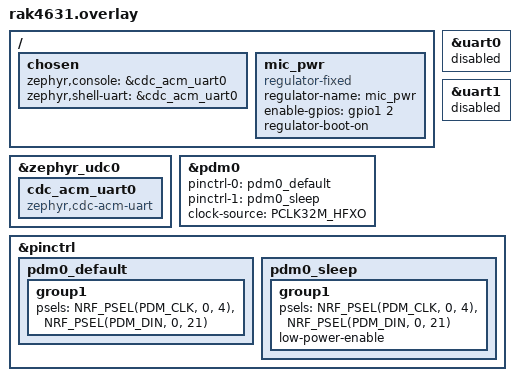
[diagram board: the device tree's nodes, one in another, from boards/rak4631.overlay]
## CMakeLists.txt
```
# SPDX-License-Identifier: Apache-2.0

cmake_minimum_required(VERSION 3.20.0)

find_package(Zephyr REQUIRED HINTS $ENV{ZEPHYR_BASE})
project(rak18030)

target_sources(app PRIVATE src/main.c)
```

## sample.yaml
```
sample:
  name: RAK18030
tests:
  sample.sensor.rak18030:
    platform_allow:
      - rak4631
    tags: rak
    build_only: true
  sample.sensor.rak18030.sleep:
    platform_allow:
      - rak4631
    extra_args: EXTRA_CONF_FILE=overlay_sleep_rak4631.conf
    tags: rak
    build_only: true
```

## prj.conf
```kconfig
CONFIG_GPIO=y
CONFIG_SPI=y
CONFIG_LORA=y
CONFIG_REGULATOR=y

CONFIG_AUDIO=y
CONFIG_AUDIO_DMIC=y

CONFIG_MAIN_STACK_SIZE=4096

CONFIG_PRINTK=y
CONFIG_BOOT_DELAY=5000

CONFIG_LOG=n
```

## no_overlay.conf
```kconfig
#The aim of this file is to use VS Code inputs.
```

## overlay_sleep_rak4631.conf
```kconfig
# Necessary options for low power consumption
CONFIG_PM_DEVICE=y
CONFIG_LOG=n
CONFIG_LOG_PRINTK=n
CONFIG_LOG_MODE_IMMEDIATE=n
CONFIG_BOOT_BANNER=n
CONFIG_DEBUG=n
CONFIG_DEBUG_THREAD_INFO=n
CONFIG_DEBUG_OPTIMIZATIONS=n
# Open to disable USB stack if you need!!!
# RAK4631 uses USB stack and it does not cause to
# increase on idle current.
# CONFIG_SERIAL=n
# CONFIG_UART_INTERRUPT_DRIVEN=n
# CONFIG_CONSOLE=n
# CONFIG_UART_CONSOLE=n
# CONFIG_RTT_CONSOLE=n
# CONFIG_USB_DEVICE_STACK=n
```

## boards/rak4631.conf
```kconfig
CONFIG_USB_DEVICE_STACK_NEXT=y
CONFIG_USB_DEVICE_REMOTE_WAKEUP=n
CONFIG_CDC_ACM_SERIAL_PRODUCT_STRING="Zephyr RTOS"
CONFIG_CDC_ACM_SERIAL_MANUFACTURER_STRING="RAKwireless"
# Use Nordic's VID and PID for development boards
CONFIG_CDC_ACM_SERIAL_VID=0x1915
CONFIG_CDC_ACM_SERIAL_PID=0x5300
CONFIG_CDC_ACM_SERIAL_INITIALIZE_AT_BOOT=y
```

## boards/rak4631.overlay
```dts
/ {
	chosen {
		zephyr,console = &cdc_acm_uart0;
		zephyr,shell-uart = &cdc_acm_uart0;
	};

	mic_pwr: mic_pwr {
		compatible = "regulator-fixed";
		regulator-name = "mic_pwr";
		enable-gpios = <&gpio1 2 GPIO_ACTIVE_HIGH>;
		regulator-boot-on;
	};
};

&zephyr_udc0 {
	cdc_acm_uart0: cdc_acm_uart0 {
		compatible = "zephyr,cdc-acm-uart";
	};
};

&uart0 {
	status = "disabled";
};

&uart1 {
	status = "disabled";
};

dmic_dev: &pdm0 {
	status = "okay";
	pinctrl-0 = <&pdm0_default>;
	pinctrl-1 = <&pdm0_sleep>;
	pinctrl-names = "default", "sleep";
	clock-source = "PCLK32M_HFXO";
};

&pinctrl {
	pdm0_default: pdm0_default {
		group1 {
			psels = <NRF_PSEL(PDM_CLK, 0, 4)>,
				<NRF_PSEL(PDM_DIN, 0, 21)>;
		};
	};

	pdm0_sleep: pdm0_sleep {
		group1 {
			psels = <NRF_PSEL(PDM_CLK, 0, 4)>,
				<NRF_PSEL(PDM_DIN, 0, 21)>;
				low-power-enable;
		};
	};
};
```

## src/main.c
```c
#include <zephyr/kernel.h>
#include <zephyr/audio/dmic.h>
#include <zephyr/drivers/gpio.h>
#include <zephyr/drivers/regulator.h>

#define AUDIO_FREQ       16000
#define NUMBER_OF_CHAN   1
#define SAMPLE_BIT_WIDTH 16
#define BYTES_PER_SAMPLE (SAMPLE_BIT_WIDTH / 8)
#define READ_TIMEOUT_MS  1000

#define BLOCK_SIZE_SAMPLES 1600 /* 100ms audio data */
#define BLOCK_SIZE_BYTES   (BLOCK_SIZE_SAMPLES * BYTES_PER_SAMPLE)
#define BLOCK_COUNT        10

#define RECORD_DURATION_SEC   6
#define RECORD_DURATION_INDEX (RECORD_DURATION_SEC * 10)

/* Define a memory slab to manage audio buffers */
K_MEM_SLAB_DEFINE(mem_slab, BLOCK_SIZE_BYTES, BLOCK_COUNT, 4);

struct pcm_stream_cfg stream = {
	.pcm_rate = AUDIO_FREQ,
	.pcm_width = SAMPLE_BIT_WIDTH,
	.block_size = BLOCK_SIZE_BYTES,
	.mem_slab = &mem_slab,
};

struct dmic_cfg cfg = {
	.io =
		{
			/* These fields can be used to limit the PDM clock
			 * configurations that the driver is allowed to use
			 * to those supported by the microphone.
			 */
			.min_pdm_clk_freq = 1000000,
			.max_pdm_clk_freq = 3500000,
			.min_pdm_clk_dc = 40,
			.max_pdm_clk_dc = 60,
		},
	.streams = &stream,
	.channel =
		{
			.req_num_chan = NUMBER_OF_CHAN,
			.req_num_streams = 1,
		},
};

const struct device *const dmic_dev = DEVICE_DT_GET(DT_NODELABEL(dmic_dev));

/*
 * Get LoRa device
 */
static const struct device *lora_dev = DEVICE_DT_GET(DT_ALIAS(lora0));

int main(void)
{
	int ret;
	uint16_t index = 0;

	if (!device_is_ready(lora_dev)) {
		printk("%s: device not ready.\n", lora_dev->name);
		return -1;
	}

	printk("DMIC sample: %s\n", CONFIG_BOARD);

	printk("Waiting for mic to stabilize...\n");
	k_msleep(100);

	if (!device_is_ready(dmic_dev)) {
		printk("%s is not ready\n", dmic_dev->name);
		return -EIO;
	}

	printk("PCM output rate: %u, channels: %u\n", cfg.streams[0].pcm_rate,
	       cfg.channel.req_num_chan);

	/* Select your mic channel */
	cfg.channel.req_chan_map_lo = dmic_build_channel_map(0, 0, PDM_CHAN_RIGHT);

	ret = dmic_configure(dmic_dev, &cfg);
	if (ret < 0) {
		printk("Failed to configure the driver: %d\n", ret);
		return ret;
	}

	ret = dmic_trigger(dmic_dev, DMIC_TRIGGER_START);
	if (ret < 0) {
		printk("START trigger failed: %d\n", ret);
		return ret;
	}

	printk("Start of mic record\n");

	while (1) {
		void *buffer;
		uint32_t size;

		ret = dmic_read(dmic_dev, 0, &buffer, &size, READ_TIMEOUT_MS);
		if (ret < 0) {
			printk("%d - read failed: %d\n", index, ret);
			continue;
		}

		int16_t *pcm_out = (int16_t *)buffer;

		for (int j = 0; j < size / 2; j++) {
			printk("%d,", pcm_out[j]);
			if ((j + 1) % 16 == 0) {
				printk("\n");
			}
		}

		k_mem_slab_free(&mem_slab, buffer);

		index++;

		if (index > RECORD_DURATION_INDEX) {
			printk("End of mic record\n");
			break;
		}
	}

	ret = dmic_trigger(dmic_dev, DMIC_TRIGGER_STOP);
	if (ret < 0) {
		printk("STOP trigger failed: %d\n", ret);
	}

	printk("Exiting\n");
	return 0;
}
```
